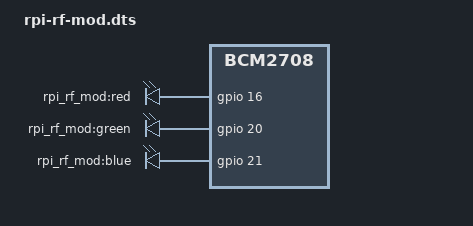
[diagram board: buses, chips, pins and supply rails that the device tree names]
/dts-v1/;
/plugin/;

/*
** Device Tree Overlay for eQ-3 RPI-RF-MOD
**
**
** Copyright (c) 2018 Jens Maus <mail@jens-maus.de>
** Licensed under Apache 2.0
**
*/

/ {
    compatible = "brcm,bcm2708";

    // fragment to ensure we have the correct gpio pin
    // setup for the RPI-RF-MOD
    fragment@1 {
        target = <&gpio>;
        __overlay__ {
            rpi_rf_mod_pins: rpi_rf_mod_pins {
                brcm,pins = <19 18 12 16 20 21>; // 19=reset, 18=reset (HM-MOD), 12=button, 16=red, 20=green, 21=blue
                brcm,pull = <0 0 2 0 0 0>; // 19,18=no-pullup, 12=pullup, 16,20,21=no-pullup
                brcm,function = <0 0 0 1 1 1>; // 19,18,12=input, 16,20,21=output
            };
        };
    };

    // fragment to define dedicated led nodes for
    // each ѕeparate led supported by the RPI-RF-MOD
    fragment@0 {
        target = <&leds>;
        __overlay__ {
            pinctrl-names = "default";
            pinctrl-0 = <&rpi_rf_mod_pins>;
            rpi_rf_mod_red: rpi_rf_mod_red {
                label = "rpi_rf_mod:red";
                gpios = <&gpio 16 0>;
                default-state = "keep";
                linux,default-trigger = "none";
            };
            rpi_rf_mod_green: rpi_rf_mod_green {
                label = "rpi_rf_mod:green";
                gpios = <&gpio 20 0>;
                default-state = "keep";
                linux,default-trigger = "none";
            };
            rpi_rf_mod_blue: rpi_rf_mod_blue {
                label = "rpi_rf_mod:blue";
                gpios = <&gpio 21 0>;
                default-state = "keep";
                linux,default-trigger = "none";
            };
        };
    };
};
